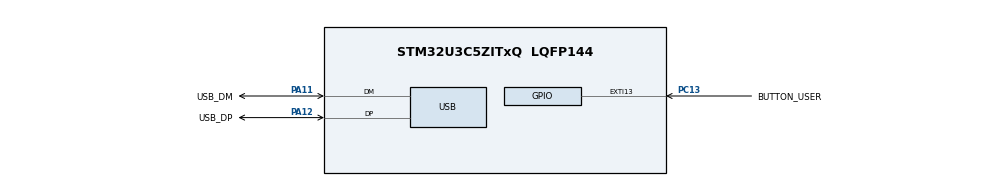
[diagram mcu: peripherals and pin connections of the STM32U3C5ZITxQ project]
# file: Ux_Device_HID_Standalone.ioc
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CORTEX_M33_NS.userName=CORTEX_M33
Mcu.Family=STM32U3
Mcu.Name=STM32U3C5ZITxQ
Mcu.Package=LQFP144
NVIC.EXTI13_IRQn=true\:7\:0\:true\:false\:true\:true\:true\:true
NVIC.PriorityGroup=NVIC_PRIORITYGROUP_4
NVIC.USB_FS_IRQn=true\:3\:0\:true\:false\:true\:true\:true\:true
PA11.GPIO_Label=USB_DM
PA11.Mode=Device
PA11.Signal=USB_DM
PA12.GPIO_Label=USB_DP
PA12.Mode=Device
PA12.Signal=USB_DP
PC13.GPIO_Label=BUTTON_USER
PC13.GPIO_PuPd=GPIO_PULLDOWN
PC13.Signal=GPXTI13
PH0-OSC_IN\ (PH0).Mode=HSE-DIG-External-Clock-Source
PH0-OSC_IN\ (PH0).Signal=RCC_OSC_IN
ProjectManager.HeapSize=0x200
ProjectManager.StackSize=0x400
ProjectManager.TargetToolchain=EWARM V9.60
RCC.ADCFreq_Value=96000000
RCC.AHBFreq_Value=96000000
RCC.APB1Freq_Value=96000000
RCC.APB1TimFreq_Value=96000000
RCC.APB2Freq_Value=96000000
RCC.APB2TimFreq_Value=96000000
RCC.APB3Freq_Value=96000000
RCC.CortexFreq_Value=12000000
RCC.HCLKFreq_Value=96000000
RCC.HSE_VALUE=16000000
RCC.HSI48_VALUE=48000000
RCC.HSI_VALUE=16000000
RCC.ICLKCLockSelection=RCC_ICLKCLKSOURCE_HSI48
RCC.LSE_VALUE=32768
RCC.LSIDIV_VALUE=32000
RCC.MSISDIV=RCC_MSI_DIV1
RCC.MSI_VALUE=96000000
RCC.PWR_Regulator_Voltage_Scale=PWR_REGULATOR_VOLTAGE_SCALE1
RCC.SYSCLKFreq_VALUE=96000000
RCC.USBFreq_Value=48000000
USB.VirtualMode=Device_Only
USBX.BSP.number=1
USBX.Core_System=1
USBX.MAX_POWER_IN_MILLI_AMPER=0
USBX.USBD_PID=22336
USBX.USBD_PRODUCT_STRING=STM32 Device HID Mouse
USBX.USBD_SERIAL_NUMBER=HID001
USBX.USBX_DEVICE_SYS_SIZE=4*1024
USBX.UX_DEVICE_APP_MEM_POOL_SIZE_STANDALONE=4*1024
USBX.UX_DEVICE_HID_CORE=1
USBX.UX_DEVICE_HID_MOUSE=1
USBX.UX_Device_Controller=1
USBX.UX_Device_CoreStack=1
USBX.UX_SLAVE_REQUEST_DATA_MAX_LENGTH=512
USBX0.BSP.STBoard=false
USBX0.BSP.api=Unknown
USBX0.BSP.instance=USB
USBX0.BSP.ip=USB
USBX0.BSP.mode=Device_Only
USBX0.BSP.name=USB_Device
USBX0.BSP.solution=USB
VP_ICACHE_VS_ICACHE.Mode=DirectMappedCache
VP_PWR_VS_DBSignals.Mode=DisableDeadBatterySignals
VP_PWR_VS_LPOM.Mode=PowerOptimisation
VP_PWR_VS_SECSignals.Mode=Security/Privilege
VP_RCC_USB.Mode=CRS SYNC Source USB
VP_USBX_Core_System.Mode=Core_System
VP_USBX_UX\ Device\ Controller_FS.Mode=UX_Device_Controller_FS
VP_USBX_UX\ Device\ CoreStack_FS.Mode=UX_Device_CoreStack_FS
VP_USBX_UX\ Device\ HID_CORE_FS.Mode=UX_Device_class_HID_CORE_FS
VP_USBX_UX\ Device\ HID_MOUSE_FS.Mode=UX_Device_class_HID_MOUSE_FS
board=custom

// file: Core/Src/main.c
/* USER CODE BEGIN Header */
/**
  ******************************************************************************
  * @file           : main.c
  * @brief          : Main program body
  ******************************************************************************
  * @attention
  *
  * Copyright (c) 2026 STMicroelectronics.
  * All rights reserved.
  *
  * This software is licensed under terms that can be found in the LICENSE file
  * in the root directory of this software component.
  * If no LICENSE file comes with this software, it is provided AS-IS.
  *
  ******************************************************************************
  */
/* USER CODE END Header */
#include "main.h"
#include "app_usbx_device.h"

PCD_HandleTypeDef hpcd_USB_DRD_FS;

void SystemClock_Config(void);
static void MX_GPIO_Init(void);
static void MX_ICACHE_Init(void);

int main(void)
{

  /* MCU Configuration--------------------------------------------------------*/

  /* Reset of all peripherals, Initializes the Flash interface and the Systick. */
  HAL_Init();

  /* Configure the system clock */
  SystemClock_Config();

  /* Initialize all configured peripherals */
  MX_GPIO_Init();
  MX_ICACHE_Init();
  MX_USBX_Device_Init();

  /* Infinite loop */
  while (1)
  {

    /* USER CODE BEGIN 3 */
    USBX_Device_Process(NULL);
  }
  /* USER CODE END 3 */
}

void SystemClock_Config(void)
{
  RCC_OscInitTypeDef RCC_OscInitStruct = {0};
  RCC_ClkInitTypeDef RCC_ClkInitStruct = {0};
  RCC_CRSInitTypeDef RCC_CRSInitStruct = {0};

  /** Configure the System Power Supply
  */
  if (HAL_PWREx_ConfigSupply(PWR_SMPS_SUPPLY) != HAL_OK)
  {
    Error_Handler();
  }

  /** Enable Epod Booster
  */
  if (HAL_RCCEx_EpodBoosterClkConfig(RCC_EPODBOOSTER_SOURCE_MSIS, RCC_EPODBOOSTER_DIV1) != HAL_OK)
  {
    Error_Handler();
  }
  if (HAL_PWREx_EnableEpodBooster() != HAL_OK)
  {
    Error_Handler();
  }

  /** Configure the main internal regulator output voltage
  */
  if (HAL_PWREx_ControlVoltageScaling(PWR_REGULATOR_VOLTAGE_SCALE1) != HAL_OK)
  {
    Error_Handler();
  }

  /** Set Flash latency before increasing MSIS
  */
  __HAL_FLASH_SET_LATENCY(FLASH_LATENCY_3);

  /** Initializes the CPU, AHB and APB buses clocks
  */
  RCC_OscInitStruct.OscillatorType = RCC_OSCILLATORTYPE_HSI48|RCC_OSCILLATORTYPE_MSIS;
  RCC_OscInitStruct.HSI48State = RCC_HSI48_ON;
  RCC_OscInitStruct.MSISState = RCC_MSI_ON;
  RCC_OscInitStruct.MSISSource = RCC_MSI_RC0;
  RCC_OscInitStruct.MSISDiv = RCC_MSI_DIV1;
  if (HAL_RCC_OscConfig(&RCC_OscInitStruct) != HAL_OK)
  {
    Error_Handler();
  }

  /** Initializes the CPU, AHB and APB buses clocks
  */
  RCC_ClkInitStruct.ClockType = RCC_CLOCKTYPE_HCLK|RCC_CLOCKTYPE_SYSCLK
                              |RCC_CLOCKTYPE_PCLK1|RCC_CLOCKTYPE_PCLK2
                              |RCC_CLOCKTYPE_PCLK3;
  RCC_ClkInitStruct.SYSCLKSource = RCC_SYSCLKSOURCE_MSIS;
  RCC_ClkInitStruct.AHBCLKDivider = RCC_SYSCLK_DIV1;
  RCC_ClkInitStruct.APB1CLKDivider = RCC_HCLK_DIV1;
  RCC_ClkInitStruct.APB2CLKDivider = RCC_HCLK_DIV1;
  RCC_ClkInitStruct.APB3CLKDivider = RCC_HCLK_DIV1;

  if (HAL_RCC_ClockConfig(&RCC_ClkInitStruct, FLASH_LATENCY_3) != HAL_OK)
  {
    Error_Handler();
  }

  /** Enable the CRS clock
  */
  __HAL_RCC_CRS_CLK_ENABLE();

  /** Configures CRS
  */
  RCC_CRSInitStruct.Prescaler = RCC_CRS_SYNC_DIV1;
  RCC_CRSInitStruct.Source = RCC_CRS_SYNC_SOURCE_USB;
  RCC_CRSInitStruct.Polarity = RCC_CRS_SYNC_POLARITY_RISING;
  RCC_CRSInitStruct.ReloadValue = __HAL_RCC_CRS_RELOADVALUE_CALCULATE(48000000,1000);
  RCC_CRSInitStruct.ErrorLimitValue = 34;
  RCC_CRSInitStruct.HSI48CalibrationValue = 32;

  HAL_RCCEx_CRSConfig(&RCC_CRSInitStruct);
}

static void MX_ICACHE_Init(void)
{

  /** Enable instruction cache in 1-way (direct mapped cache)
  */
  if (HAL_ICACHE_ConfigAssociativityMode(ICACHE_1WAY) != HAL_OK)
  {
    Error_Handler();
  }
  if (HAL_ICACHE_Enable() != HAL_OK)
  {
    Error_Handler();
  }

}

void MX_USB_PCD_Init(void)
{

  hpcd_USB_DRD_FS.Instance = USB_DRD_FS;
  hpcd_USB_DRD_FS.Init.dev_endpoints = 8;
  hpcd_USB_DRD_FS.Init.speed = USBD_FS_SPEED;
  hpcd_USB_DRD_FS.Init.phy_itface = PCD_PHY_EMBEDDED;
  hpcd_USB_DRD_FS.Init.Sof_enable = DISABLE;
  hpcd_USB_DRD_FS.Init.low_power_enable = DISABLE;
  hpcd_USB_DRD_FS.Init.lpm_enable = DISABLE;
  hpcd_USB_DRD_FS.Init.battery_charging_enable = DISABLE;
  hpcd_USB_DRD_FS.Init.vbus_sensing_enable = DISABLE;
  hpcd_USB_DRD_FS.Init.bulk_doublebuffer_enable = DISABLE;
  hpcd_USB_DRD_FS.Init.iso_singlebuffer_enable = DISABLE;
  if (HAL_PCD_Init(&hpcd_USB_DRD_FS) != HAL_OK)
  {
    Error_Handler();
  }

}

static void MX_GPIO_Init(void)
{
  GPIO_InitTypeDef GPIO_InitStruct = {0};

  /* GPIO Ports Clock Enable */
  __HAL_RCC_GPIOC_CLK_ENABLE();
  __HAL_RCC_GPIOA_CLK_ENABLE();

  /*Configure GPIO pin : BUTTON_USER_Pin */
  GPIO_InitStruct.Pin = BUTTON_USER_Pin;
  GPIO_InitStruct.Mode = GPIO_MODE_IT_RISING;
  GPIO_InitStruct.Pull = GPIO_PULLDOWN;
  HAL_GPIO_Init(BUTTON_USER_GPIO_Port, &GPIO_InitStruct);

  /* EXTI interrupt init*/
  HAL_NVIC_SetPriority(BUTTON_USER_EXTI_IRQn, 7, 0);
  HAL_NVIC_EnableIRQ(BUTTON_USER_EXTI_IRQn);

}

void Error_Handler(void)
{
  while (1)
  {
  }
}
#ifdef USE_FULL_ASSERT
/**
  * @brief  Reports the name of the source file and the source line number
  *         where the assert_param error has occurred.
  * @param  file: pointer to the source file name
  * @param  line: assert_param error line source number
  * @retval None
  */
void assert_failed(uint8_t *file, uint32_t line)
{
  /* USER CODE BEGIN 6 */
  /* User can add his own implementation to report the file name and line number,
     ex: printf("Wrong parameters value: file %s on line %d\r\n", file, line) */
  /*Infinite loop */
  while (1)
  {
  }
  /* USER CODE END 6 */
}
#endif /* USE_FULL_ASSERT */
